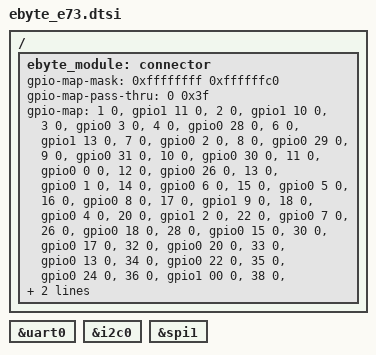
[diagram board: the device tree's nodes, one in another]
/*
 * Copyright (c) 2020 Richard Osterloh <richard.osterloh@gmail.com>
 *
 * SPDX-License-Identifier: Apache-2.0
 */

/ {
	ebyte_module: connector {
		#gpio-cells = <2>;
		gpio-map-mask = <0xffffffff 0xffffffc0>;
		gpio-map-pass-thru = <0 0x3f>;
		gpio-map = <1  0 &gpio1 11 0>,	/* SCL */
			   <2  0 &gpio1 10 0>,	/* SDA */
			   <3  0 &gpio0  3 0>,	/* INT */
			   <4  0 &gpio0 28 0>,	
			   /* 5=GND */
			   <6  0 &gpio1 13 0>,
			   <7  0 &gpio0  2 0>,
			   <8  0 &gpio0 29 0>,
			   <9  0 &gpio0 31 0>,
			   <10 0 &gpio0 30 0>,
			   <11 0 &gpio0  0 0>, /* tx */
			   <12 0 &gpio0 26 0>, 
			   <13 0 &gpio0  1 0>, /* rx */
			   <14 0 &gpio0  6 0>,
			   <15 0 &gpio0  5 0>, /* batt sens */
			   <16 0 &gpio0  8 0>,
			   <17 0 &gpio1  9 0>,
			   <18 0 &gpio0  4 0>,
			   /* 19 = VDD */
			   <20 0 &gpio1  2 0>,
			   /* 21 = GND */
			   <22 0 &gpio0  7 0>,
			   /* 23 = VDDH */
			   /* 24 = GND */
			   /* 25 = DCH */
			   <26 0 &gpio0 18 0>,
			   /* 27 = VBUS */
			   <28 0 &gpio0 15 0>,
			   /* 29 = D- */
			   <30 0 &gpio0 17 0>,
			   /* 31 = D+ */
			   <32 0 &gpio0 20 0>,
			   <33 0 &gpio0 13 0>,
			   <34 0 &gpio0 22 0>,
			   <35 0 &gpio0 24 0>,
			   <36 0 &gpio1 00 0>,
			   /* 37 = SWDIO */
			   <38 0 &gpio1  2 0>,
			   /* 39 = SWDCLK */
			   <40 0 &gpio1  4 0>,
			   <41 0 &gpio0  9 0>,
			   <42 0 &gpio1  6 0>,
			   <43 0 &gpio0 10 0>;
	};
};

ebyte_serial: &uart0 {};
ebyte_i2c: &i2c0 {};
ebyte_spi: &spi1 {};
